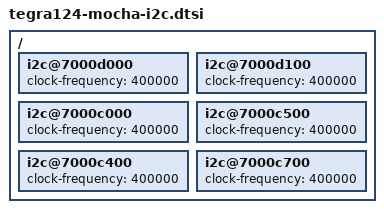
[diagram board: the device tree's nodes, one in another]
/ {
	/* Expansion PWR_I2C_*, on-board components */
	i2c@7000d000 {
		clock-frequency = <400000>;
		status = "okay";
	};

	i2c@7000d100 {
		status = "okay";
		clock-frequency = <400000>;
	};

	i2c@7000c000 {
		status = "okay";
		clock-frequency = <400000>;
	};

	i2c@7000c500 {
		status = "okay";
		clock-frequency = <400000>;
	};

	i2c@7000c400 {
		status = "okay";
		clock-frequency = <400000>;
	};

	i2c@7000c700 {
		status = "okay";
		clock-frequency = <400000>;
	};
};
